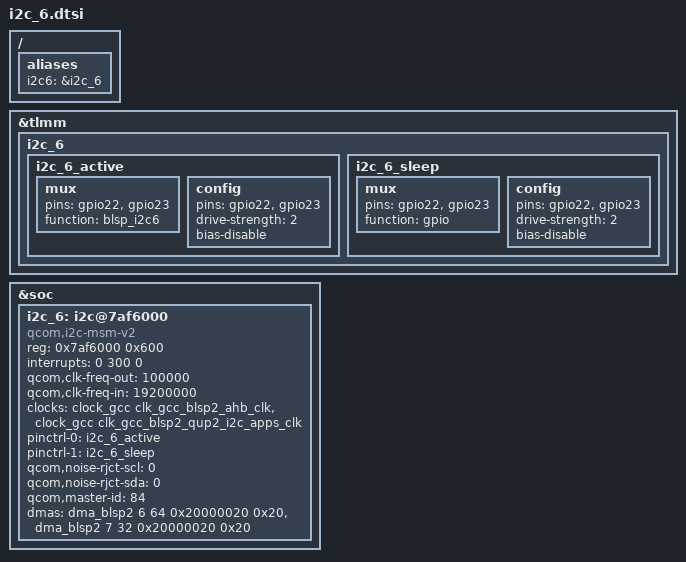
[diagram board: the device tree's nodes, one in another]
/* TODO: Delete this, is useless */
/ {
	aliases {
		i2c6 = &i2c_6;
	};
};
&tlmm {
	i2c_6 {
		i2c_6_active: i2c_6_active {
			mux {
				pins = "gpio22", "gpio23";
				function = "blsp_i2c6";
			};

			config {
				pins = "gpio22", "gpio23";
				drive-strength = <2>;
				bias-disable;
			};
		};

		i2c_6_sleep: i2c_6_sleep {
			mux {
				pins = "gpio22", "gpio23";
				function = "gpio";
			};

			config {
				pins = "gpio22", "gpio23";
				drive-strength = <2>;
				bias-disable;
			};
		};
	};
};
&soc {
	i2c_6: i2c@7af6000 {
		compatible = "qcom,i2c-msm-v2";
		#address-cells = <1>;
		#size-cells = <0>;
		reg-names = "qup_phys_addr";
		reg = <0x7af6000 0x600>;
		interrupt-names = "qup_irq";
		interrupts = <0 300 0>;
		qcom,clk-freq-out = <100000>;
		qcom,clk-freq-in  = <19200000>;
		clock-names = "iface_clk", "core_clk";
		clocks = <&clock_gcc clk_gcc_blsp2_ahb_clk>,
			<&clock_gcc clk_gcc_blsp2_qup2_i2c_apps_clk>;

		pinctrl-names = "i2c_active", "i2c_sleep";
		pinctrl-0 = <&i2c_6_active>;
		pinctrl-1 = <&i2c_6_sleep>;
		qcom,noise-rjct-scl = <0>;
		qcom,noise-rjct-sda = <0>;
		qcom,master-id = <84>;
		dmas = <&dma_blsp2 6 64 0x20000020 0x20>,
			<&dma_blsp2 7 32 0x20000020 0x20>;
		dma-names = "tx", "rx";
		status = "ok";
	};
};
